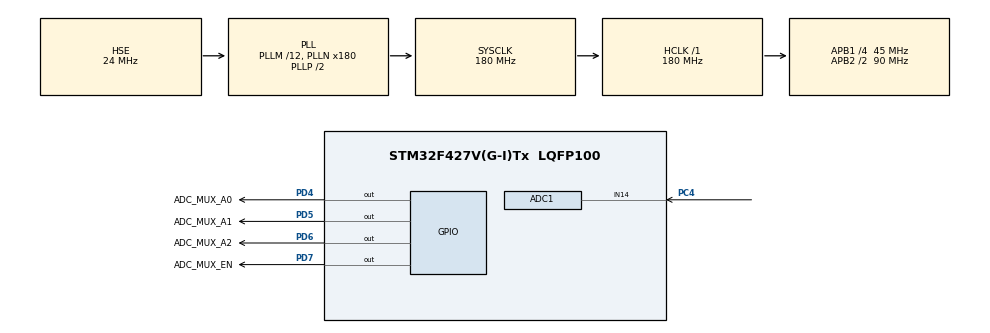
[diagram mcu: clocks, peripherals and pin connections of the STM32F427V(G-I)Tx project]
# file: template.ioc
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ADC1.Channel-0\#ChannelRegularConversion=ADC_CHANNEL_14
ADC1.ContinuousConvMode=ENABLE
ADC1.DMAContinuousRequests=ENABLE
ADC1.NbrOfConversionFlag=1
ADC1.Rank-0\#ChannelRegularConversion=1
ADC1.SamplingTime-0\#ChannelRegularConversion=ADC_SAMPLETIME_3CYCLES
ADC1.master=1
Dma.ADC1.0.Direction=DMA_PERIPH_TO_MEMORY
Dma.ADC1.0.FIFOMode=DMA_FIFOMODE_DISABLE
Dma.ADC1.0.Instance=DMA2_Stream0
Dma.ADC1.0.MemDataAlignment=DMA_MDATAALIGN_HALFWORD
Dma.ADC1.0.MemInc=DMA_MINC_ENABLE
Dma.ADC1.0.Mode=DMA_CIRCULAR
Dma.ADC1.0.PeriphDataAlignment=DMA_PDATAALIGN_HALFWORD
Dma.ADC1.0.PeriphInc=DMA_PINC_DISABLE
Dma.ADC1.0.Priority=DMA_PRIORITY_LOW
Dma.Request0=ADC1
Mcu.Family=STM32F4
Mcu.Name=STM32F427V(G-I)Tx
Mcu.Package=LQFP100
NVIC.DMA2_Stream0_IRQn=true\:0\:0\:false\:false\:true\:false\:true
NVIC.PriorityGroup=NVIC_PRIORITYGROUP_4
PA13.Mode=Serial_Wire
PA13.Signal=SYS_JTMS-SWDIO
PA14.Mode=Serial_Wire
PA14.Signal=SYS_JTCK-SWCLK
PC4.Signal=ADCx_IN14
PD4.GPIO_Label=ADC_MUX_A0
PD4.GPIO_ModeDefaultOutputPP=GPIO_MODE_OUTPUT_PP
PD4.GPIO_PuPd=GPIO_PULLDOWN
PD4.GPIO_Speed=GPIO_SPEED_FREQ_HIGH
PD4.Signal=GPIO_Output
PD5.GPIO_Label=ADC_MUX_A1
PD5.GPIO_PuPd=GPIO_PULLDOWN
PD5.GPIO_Speed=GPIO_SPEED_FREQ_HIGH
PD5.Signal=GPIO_Output
PD6.GPIO_Label=ADC_MUX_A2
PD6.GPIO_PuPd=GPIO_PULLDOWN
PD6.GPIO_Speed=GPIO_SPEED_FREQ_HIGH
PD6.Signal=GPIO_Output
PD7.GPIO_Label=ADC_MUX_EN
PD7.GPIO_PuPd=GPIO_PULLUP
PD7.GPIO_Speed=GPIO_SPEED_FREQ_HIGH
PD7.PinState=GPIO_PIN_SET
PD7.Signal=GPIO_Output
PH0/OSC_IN.Mode=HSE-External-Oscillator
PH0/OSC_IN.Signal=RCC_OSC_IN
PH1/OSC_OUT.Mode=HSE-External-Oscillator
PH1/OSC_OUT.Signal=RCC_OSC_OUT
ProjectManager.HeapSize=0x200
ProjectManager.StackSize=0x400
ProjectManager.TargetToolchain=MDK-ARM V5
RCC.48MHZClocksFreq_Value=90000000
RCC.AHBFreq_Value=180000000
RCC.APB1CLKDivider=RCC_HCLK_DIV4
RCC.APB1Freq_Value=45000000
RCC.APB1TimFreq_Value=90000000
RCC.APB2CLKDivider=RCC_HCLK_DIV2
RCC.APB2Freq_Value=90000000
RCC.APB2TimFreq_Value=180000000
RCC.CortexFreq_Value=180000000
RCC.HCLKFreq_Value=180000000
RCC.HSE_VALUE=24000000
RCC.HSI_VALUE=16000000
RCC.LSE_VALUE=32768
RCC.PLLM=12
RCC.PLLN=180
RCC.PLLSourceVirtual=RCC_PLLSOURCE_HSE
RCC.SYSCLKFreq_VALUE=180000000
RCC.SYSCLKSource=RCC_SYSCLKSOURCE_PLLCLK
RCC.VCOOutputFreq_Value=360000000
SH.ADCx_IN14.0=ADC1_IN14,IN14
board=custom

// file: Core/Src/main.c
/* USER CODE BEGIN Header */
/**
  ******************************************************************************
  * @file           : main.c
  * @brief          : Main program body
  ******************************************************************************
  * @attention
  *
  * <h2><center>&copy; Copyright (c) 2022 STMicroelectronics.
  * All rights reserved.</center></h2>
  *
  * This software component is licensed by ST under BSD 3-Clause license,
  * the "License"; You may not use this file except in compliance with the
  * License. You may obtain a copy of the License at:
  *                        opensource.org/licenses/BSD-3-Clause
  *
  ******************************************************************************
  */
/* USER CODE END Header */
#include "main.h"
#include "adc.h"
#include "dma.h"
#include "gpio.h"

/* USER CODE BEGIN Includes */
#include "adc_data.h"

/* USER CODE END Includes */

/* USER CODE BEGIN PTD */

extern uint8_t channel;

/* USER CODE END PTD */

void SystemClock_Config(void);

int main(void)
{

  /* MCU Configuration--------------------------------------------------------*/

  /* Reset of all peripherals, Initializes the Flash interface and the Systick. */
  HAL_Init();

  /* Configure the system clock */
  SystemClock_Config();

  /* Initialize all configured peripherals */
  MX_GPIO_Init();
  MX_DMA_Init();
  MX_ADC1_Init();

  /* Infinite loop */
  /* USER CODE BEGIN WHILE */
    while (1)
    {
        HAL_Delay(50);
        mux_get_ADC_channel_data(&channel);
    /* USER CODE END WHILE */

    }
}

void SystemClock_Config(void)
{
  RCC_OscInitTypeDef RCC_OscInitStruct = {0};
  RCC_ClkInitTypeDef RCC_ClkInitStruct = {0};

  /** Configure the main internal regulator output voltage
  */
  __HAL_RCC_PWR_CLK_ENABLE();
  __HAL_PWR_VOLTAGESCALING_CONFIG(PWR_REGULATOR_VOLTAGE_SCALE1);
  /** Initializes the RCC Oscillators according to the specified parameters
  * in the RCC_OscInitTypeDef structure.
  */
  RCC_OscInitStruct.OscillatorType = RCC_OSCILLATORTYPE_HSE;
  RCC_OscInitStruct.HSEState = RCC_HSE_ON;
  RCC_OscInitStruct.PLL.PLLState = RCC_PLL_ON;
  RCC_OscInitStruct.PLL.PLLSource = RCC_PLLSOURCE_HSE;
  RCC_OscInitStruct.PLL.PLLM = 12;
  RCC_OscInitStruct.PLL.PLLN = 180;
  RCC_OscInitStruct.PLL.PLLP = RCC_PLLP_DIV2;
  RCC_OscInitStruct.PLL.PLLQ = 4;
  if (HAL_RCC_OscConfig(&RCC_OscInitStruct) != HAL_OK)
  {
    Error_Handler();
  }
  /** Activate the Over-Drive mode
  */
  if (HAL_PWREx_EnableOverDrive() != HAL_OK)
  {
    Error_Handler();
  }
  /** Initializes the CPU, AHB and APB buses clocks
  */
  RCC_ClkInitStruct.ClockType = RCC_CLOCKTYPE_HCLK|RCC_CLOCKTYPE_SYSCLK
                              |RCC_CLOCKTYPE_PCLK1|RCC_CLOCKTYPE_PCLK2;
  RCC_ClkInitStruct.SYSCLKSource = RCC_SYSCLKSOURCE_PLLCLK;
  RCC_ClkInitStruct.AHBCLKDivider = RCC_SYSCLK_DIV1;
  RCC_ClkInitStruct.APB1CLKDivider = RCC_HCLK_DIV4;
  RCC_ClkInitStruct.APB2CLKDivider = RCC_HCLK_DIV2;

  if (HAL_RCC_ClockConfig(&RCC_ClkInitStruct, FLASH_LATENCY_5) != HAL_OK)
  {
    Error_Handler();
  }
}

void Error_Handler(void)
{
  __disable_irq();
  while (1)
  {
  }
}

/************************ (C) COPYRIGHT STMicroelectronics *****END OF FILE****/
